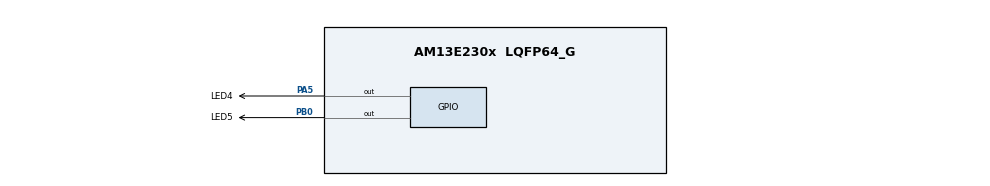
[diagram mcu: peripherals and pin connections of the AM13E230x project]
/**
 * @cliArgs --device "AM13E230x" --part "AM13E230x" --package "LQFP64_G" --product "AM13E2X SDK@26.00.00"
 * @versions {"tool":"1.27.0+4565"}
 */

/**
 * Import the modules used in this configuration.
 */
const gpio   = scripting.addModule("/drivers/gpio", {}, false);
const gpio1  = gpio.addInstance();
const sysctl = scripting.addModule("/drivers/sysctl");

/**
 * Write custom configuration values to the imported modules.
 */
gpio1.$name                          = "GPIO_LEDS";
gpio1.associatedPins.create(2);
gpio1.associatedPins[0].$name        = "LED4";
gpio1.associatedPins[0].initialValue = "SET";
gpio1.associatedPins[0].pin.$assign  = "PA5";
gpio1.associatedPins[1].$name        = "LED5";
gpio1.associatedPins[1].initialValue = "SET";
gpio1.associatedPins[1].pin.$assign  = "PB0";

sysctl.useHFCLK     = true;
sysctl.SYSPLLSource = "DL_SYSCTL_SYSPLL_REF_HFCLK";
sysctl.SYSPLL_Qdiv  = 32;

/**
 * Pinmux solution for unlocked pins/peripherals. This ensures that minor changes to the automatic solver in a future
 * version of the tool will not impact the pinmux you originally saw.  These lines can be completely deleted in order to
 * re-solve from scratch.
 */
sysctl.peripheral.$suggestSolution       = "SYSCTL";
sysctl.peripheral.x1Pin.$suggestSolution = "PC16_X1";
sysctl.peripheral.x2Pin.$suggestSolution = "PC17_X2";
